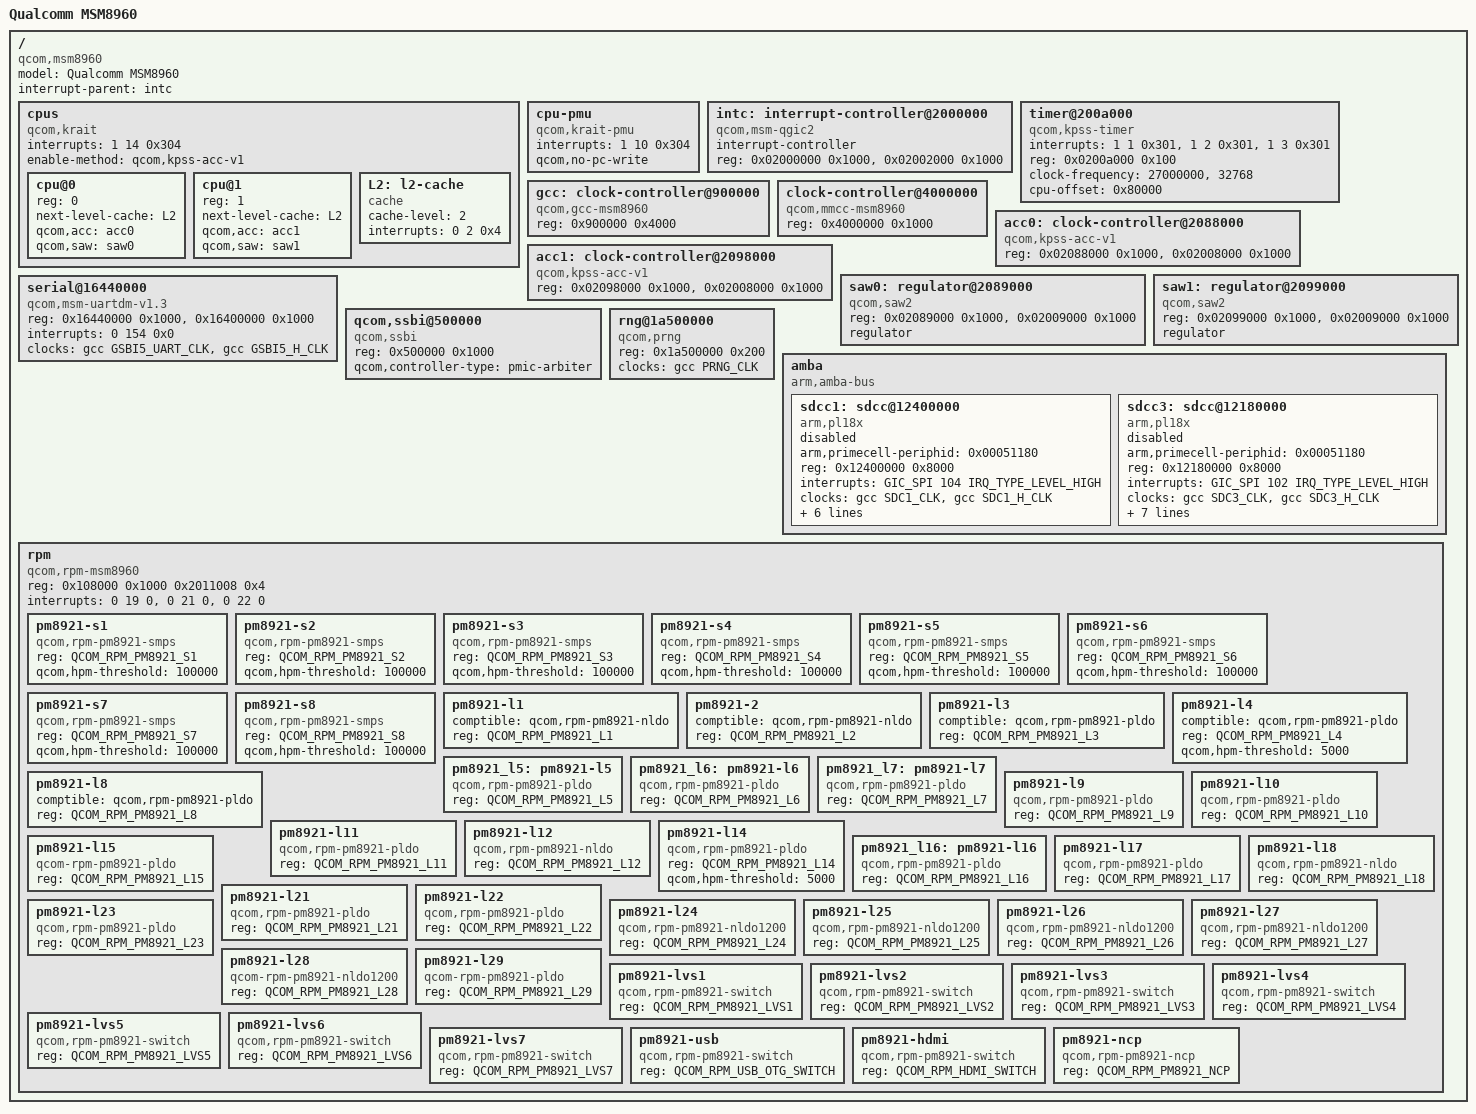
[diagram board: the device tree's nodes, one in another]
/dts-v1/;

/include/ "skeleton.dtsi"

#include <dt-bindings/interrupt-controller/arm-gic.h>
#include <dt-bindings/clock/qcom,gcc-msm8960.h>

#include <dt-bindings/mfd/qcom_rpm.h>

/ {
	model = "Qualcomm MSM8960";
	compatible = "qcom,msm8960";
	interrupt-parent = <&intc>;

	cpus {
		#address-cells = <1>;
		#size-cells = <0>;
		interrupts = <1 14 0x304>;
		compatible = "qcom,krait";
		enable-method = "qcom,kpss-acc-v1";

		cpu@0 {
			device_type = "cpu";
			reg = <0>;
			next-level-cache = <&L2>;
			qcom,acc = <&acc0>;
			qcom,saw = <&saw0>;
		};

		cpu@1 {
			device_type = "cpu";
			reg = <1>;
			next-level-cache = <&L2>;
			qcom,acc = <&acc1>;
			qcom,saw = <&saw1>;
		};

		L2: l2-cache {
			compatible = "cache";
			cache-level = <2>;
			interrupts = <0 2 0x4>;
		};
	};

	cpu-pmu {
		compatible = "qcom,krait-pmu";
		interrupts = <1 10 0x304>;
		qcom,no-pc-write;
	};

	intc: interrupt-controller@2000000 {
		compatible = "qcom,msm-qgic2";
		interrupt-controller;
		#interrupt-cells = <3>;
		reg = < 0x02000000 0x1000 >,
		      < 0x02002000 0x1000 >;
	};

	timer@200a000 {
		compatible = "qcom,kpss-timer", "qcom,msm-timer";
		interrupts = <1 1 0x301>,
			     <1 2 0x301>,
			     <1 3 0x301>;
		reg = <0x0200a000 0x100>;
		clock-frequency = <27000000>,
				  <32768>;
		cpu-offset = <0x80000>;
	};

	gcc: clock-controller@900000 {
		compatible = "qcom,gcc-msm8960";
		#clock-cells = <1>;
		#reset-cells = <1>;
		reg = <0x900000 0x4000>;
	};

	clock-controller@4000000 {
		compatible = "qcom,mmcc-msm8960";
		reg = <0x4000000 0x1000>;
		#clock-cells = <1>;
		#reset-cells = <1>;
	};

	acc0: clock-controller@2088000 {
		compatible = "qcom,kpss-acc-v1";
		reg = <0x02088000 0x1000>, <0x02008000 0x1000>;
	};

	acc1: clock-controller@2098000 {
		compatible = "qcom,kpss-acc-v1";
		reg = <0x02098000 0x1000>, <0x02008000 0x1000>;
	};

	saw0: regulator@2089000 {
		compatible = "qcom,saw2";
		reg = <0x02089000 0x1000>, <0x02009000 0x1000>;
		regulator;
	};

	saw1: regulator@2099000 {
		compatible = "qcom,saw2";
		reg = <0x02099000 0x1000>, <0x02009000 0x1000>;
		regulator;
	};

	serial@16440000 {
		compatible = "qcom,msm-uartdm-v1.3", "qcom,msm-uartdm";
		reg = <0x16440000 0x1000>,
		      <0x16400000 0x1000>;
		interrupts = <0 154 0x0>;
		clocks = <&gcc GSBI5_UART_CLK>, <&gcc GSBI5_H_CLK>;
		clock-names = "core", "iface";
	};

	qcom,ssbi@500000 {
		compatible = "qcom,ssbi";
		reg = <0x500000 0x1000>;
		qcom,controller-type = "pmic-arbiter";
	};

	rng@1a500000 {
		compatible = "qcom,prng";
		reg = <0x1a500000 0x200>;
		clocks = <&gcc PRNG_CLK>;
		clock-names = "core";
	};

	amba {
		compatible = "arm,amba-bus";
		#address-cells = <1>;
		#size-cells = <1>;
		ranges;

		sdcc1: sdcc@12400000 {
			status          = "disabled";
			compatible      = "arm,pl18x", "arm,primecell";
			arm,primecell-periphid = <0x00051180>;
			reg             = <0x12400000 0x8000>;
			interrupts      = <GIC_SPI 104 IRQ_TYPE_LEVEL_HIGH>;
			interrupt-names = "cmd_irq";
			clocks          = <&gcc SDC1_CLK>, <&gcc SDC1_H_CLK>;
			clock-names     = "mclk", "apb_pclk";
			bus-width       = <8>;
			max-frequency   = <96000000>;
			non-removable;
			cap-sd-highspeed;
			cap-mmc-highspeed;
			vmmc-supply = <&pm8921_l5>;
		};

		sdcc3: sdcc@12180000 {
			compatible      = "arm,pl18x", "arm,primecell";
			arm,primecell-periphid = <0x00051180>;
			status          = "disabled";
			reg             = <0x12180000 0x8000>;
			interrupts      = <GIC_SPI 102 IRQ_TYPE_LEVEL_HIGH>;
			interrupt-names = "cmd_irq";
			clocks          = <&gcc SDC3_CLK>, <&gcc SDC3_H_CLK>;
			clock-names     = "mclk", "apb_pclk";
			bus-width       = <4>;
			cap-sd-highspeed;
			cap-mmc-highspeed;
			max-frequency   = <192000000>;
			no-1-8-v;
			vmmc-supply = <&pm8921_l6>;
			vqmmc-supply = <&pm8921_l7>;
		};
	};

	rpm {
		compatible = "qcom,rpm-msm8960";
		reg = <0x108000 0x1000 0x2011008 0x4>;

		interrupts = <0 19 0>, <0 21 0>, <0 22 0>;
		interrupt-names = "ack", "err", "wakeup";

		#address-cells = <1>;
		#size-cells = <0>;

		pm8921-s1 {
			compatible = "qcom,rpm-pm8921-smps";
			reg = <QCOM_RPM_PM8921_S1>;

			qcom,hpm-threshold = <100000>;
		};

		pm8921-s2 {
			compatible = "qcom,rpm-pm8921-smps";
			reg = <QCOM_RPM_PM8921_S2>;

			qcom,hpm-threshold = <100000>;
		};

		pm8921-s3 {
			compatible = "qcom,rpm-pm8921-smps";
			reg = <QCOM_RPM_PM8921_S3>;

			qcom,hpm-threshold = <100000>;
		};

		pm8921-s4 {
			compatible = "qcom,rpm-pm8921-smps";
			reg = <QCOM_RPM_PM8921_S4>;

			qcom,hpm-threshold = <100000>;
		};

		pm8921-s5 {
			compatible = "qcom,rpm-pm8921-smps";
			reg = <QCOM_RPM_PM8921_S5>;

			qcom,hpm-threshold = <100000>;
		};

		pm8921-s6 {
			compatible = "qcom,rpm-pm8921-smps";
			reg = <QCOM_RPM_PM8921_S6>;

			qcom,hpm-threshold = <100000>;
		};

		pm8921-s7 {
			compatible = "qcom,rpm-pm8921-smps";
			reg = <QCOM_RPM_PM8921_S7>;

			qcom,hpm-threshold = <100000>;
		};

		pm8921-s8 {
			compatible = "qcom,rpm-pm8921-smps";
			reg = <QCOM_RPM_PM8921_S8>;

			qcom,hpm-threshold = <100000>;
		};

		pm8921-l1 {
			comptible = "qcom,rpm-pm8921-nldo";
			reg = <QCOM_RPM_PM8921_L1>;
		};

		pm8921-2 {
			comptible = "qcom,rpm-pm8921-nldo";
			reg = <QCOM_RPM_PM8921_L2>;
		};

		pm8921-l3 {
			comptible = "qcom,rpm-pm8921-pldo";
			reg = <QCOM_RPM_PM8921_L3>;
		};

		pm8921-l4 {
			comptible = "qcom,rpm-pm8921-pldo";
			reg = <QCOM_RPM_PM8921_L4>;

			qcom,hpm-threshold = <5000>;
		};

		pm8921_l5: pm8921-l5 {
			compatible = "qcom,rpm-pm8921-pldo";
			reg = <QCOM_RPM_PM8921_L5>;
		};

		pm8921_l6: pm8921-l6 {
			compatible = "qcom,rpm-pm8921-pldo";
			reg = <QCOM_RPM_PM8921_L6>;
		};

		pm8921_l7: pm8921-l7 {
			compatible = "qcom,rpm-pm8921-pldo";
			reg = <QCOM_RPM_PM8921_L7>;
		};

		pm8921-l8 {
			comptible = "qcom,rpm-pm8921-pldo";
			reg = <QCOM_RPM_PM8921_L8>;
		};

		pm8921-l9 {
			compatible = "qcom,rpm-pm8921-pldo";
			reg = <QCOM_RPM_PM8921_L9>;
		};

		pm8921-l10 {
			compatible = "qcom,rpm-pm8921-pldo";
			reg = <QCOM_RPM_PM8921_L10>;
		};

		pm8921-l11 {
			compatible = "qcom,rpm-pm8921-pldo";
			reg = <QCOM_RPM_PM8921_L11>;
		};

		pm8921-l12 {
			compatible = "qcom,rpm-pm8921-nldo";
			reg = <QCOM_RPM_PM8921_L12>;
		};

		pm8921-l14 {
			compatible = "qcom,rpm-pm8921-pldo";
			reg = <QCOM_RPM_PM8921_L14>;

			qcom,hpm-threshold = <5000>;
		};

		pm8921-l15 {
			compatible = "qcom-rpm-pm8921-pldo";
			reg = <QCOM_RPM_PM8921_L15>;
		};

		pm8921_l16: pm8921-l16 {
			compatible = "qcom,rpm-pm8921-pldo";
			reg = <QCOM_RPM_PM8921_L16>;
		};

		pm8921-l17 {
			compatible = "qcom,rpm-pm8921-pldo";
			reg = <QCOM_RPM_PM8921_L17>;
		};

		pm8921-l18 {
			compatible = "qcom,rpm-pm8921-nldo";
			reg = <QCOM_RPM_PM8921_L18>;
		};

		pm8921-l21 {
			compatible = "qcom,rpm-pm8921-pldo";
			reg = <QCOM_RPM_PM8921_L21>;
		};

		pm8921-l22 {
			compatible = "qcom,rpm-pm8921-pldo";
			reg = <QCOM_RPM_PM8921_L22>;
		};

		pm8921-l23 {
			compatible = "qcom,rpm-pm8921-pldo";
			reg = <QCOM_RPM_PM8921_L23>;
		};

		pm8921-l24 {
			compatible = "qcom,rpm-pm8921-nldo1200";
			reg = <QCOM_RPM_PM8921_L24>;
		};

		pm8921-l25 {
			compatible = "qcom,rpm-pm8921-nldo1200";
			reg = <QCOM_RPM_PM8921_L25>;
		};

		pm8921-l26 {
			compatible = "qcom,rpm-pm8921-nldo1200";
			reg = <QCOM_RPM_PM8921_L26>;
		};

		pm8921-l27 {
			compatible = "qcom,rpm-pm8921-nldo1200";
			reg = <QCOM_RPM_PM8921_L27>;
		};

		pm8921-l28 {
			compatible = "qcom-rpm-pm8921-nldo1200";
			reg = <QCOM_RPM_PM8921_L28>;
		};

		pm8921-l29 {
			compatible = "qcom-rpm-pm8921-pldo";
			reg = <QCOM_RPM_PM8921_L29>;
		};

		pm8921-lvs1 {
			compatible = "qcom,rpm-pm8921-switch";
			reg = <QCOM_RPM_PM8921_LVS1>;
		};

		pm8921-lvs2 {
			compatible = "qcom,rpm-pm8921-switch";
			reg = <QCOM_RPM_PM8921_LVS2>;
		};

		pm8921-lvs3 {
			compatible = "qcom,rpm-pm8921-switch";
			reg = <QCOM_RPM_PM8921_LVS3>;
		};

		pm8921-lvs4 {
			compatible = "qcom,rpm-pm8921-switch";
			reg = <QCOM_RPM_PM8921_LVS4>;
		};

		pm8921-lvs5 {
			compatible = "qcom,rpm-pm8921-switch";
			reg = <QCOM_RPM_PM8921_LVS5>;
		};

		pm8921-lvs6 {
			compatible = "qcom,rpm-pm8921-switch";
			reg = <QCOM_RPM_PM8921_LVS6>;
		};

		pm8921-lvs7 {
			compatible = "qcom,rpm-pm8921-switch";
			reg = <QCOM_RPM_PM8921_LVS7>;
		};

		pm8921-usb {
			compatible = "qcom,rpm-pm8921-switch";
			reg = <QCOM_RPM_USB_OTG_SWITCH>;
		};

		pm8921-hdmi {
			compatible = "qcom,rpm-pm8921-switch";
			reg = <QCOM_RPM_HDMI_SWITCH>;
		};

		pm8921-ncp {
			compatible = "qcom,rpm-pm8921-ncp";
			reg = <QCOM_RPM_PM8921_NCP>;
		};
	};

};
